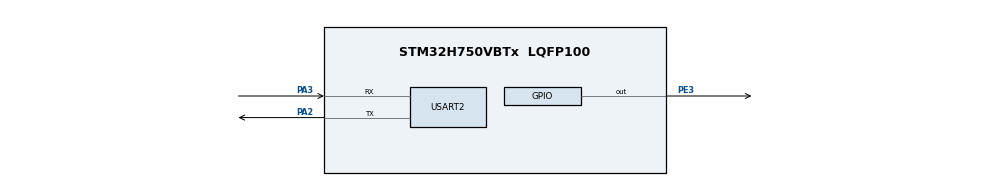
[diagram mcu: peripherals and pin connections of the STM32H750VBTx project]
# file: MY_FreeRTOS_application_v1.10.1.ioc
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CORTEX_M7.AccessPermission-Cortex_Memory_Protection_Unit_Region0_Settings=MPU_REGION_FULL_ACCESS
CORTEX_M7.AccessPermission-Cortex_Memory_Protection_Unit_Region1_Settings=MPU_REGION_FULL_ACCESS
CORTEX_M7.BaseAddress-Cortex_Memory_Protection_Unit_Region0_Settings=0x90000000
CORTEX_M7.BaseAddress-Cortex_Memory_Protection_Unit_Region1_Settings=0x90000000
CORTEX_M7.CPU_DCache=Enabled
CORTEX_M7.CPU_ICache=Enabled
CORTEX_M7.DisableExec-Cortex_Memory_Protection_Unit_Region0_Settings=MPU_INSTRUCTION_ACCESS_DISABLE
CORTEX_M7.DisableExec-Cortex_Memory_Protection_Unit_Region1_Settings=MPU_INSTRUCTION_ACCESS_ENABLE
CORTEX_M7.Enable-Cortex_Memory_Protection_Unit_Region0_Settings=MPU_REGION_ENABLE
CORTEX_M7.Enable-Cortex_Memory_Protection_Unit_Region1_Settings=MPU_REGION_ENABLE
CORTEX_M7.IsBufferable-Cortex_Memory_Protection_Unit_Region0_Settings=MPU_ACCESS_BUFFERABLE
CORTEX_M7.IsBufferable-Cortex_Memory_Protection_Unit_Region1_Settings=MPU_ACCESS_BUFFERABLE
CORTEX_M7.IsCacheable-Cortex_Memory_Protection_Unit_Region0_Settings=MPU_ACCESS_CACHEABLE
CORTEX_M7.IsCacheable-Cortex_Memory_Protection_Unit_Region1_Settings=MPU_ACCESS_CACHEABLE
CORTEX_M7.IsShareable-Cortex_Memory_Protection_Unit_Region1_Settings=MPU_ACCESS_NOT_SHAREABLE
CORTEX_M7.MPU_Control=MPU_PRIVILEGED_DEFAULT
CORTEX_M7.Size-Cortex_Memory_Protection_Unit_Region0_Settings=MPU_REGION_SIZE_8MB
CORTEX_M7.Size-Cortex_Memory_Protection_Unit_Region1_Settings=MPU_REGION_SIZE_1MB
FREERTOS.Tasks01=defaultTask,24,128,StartDefaultTask,Default,NULL,Dynamic,NULL,NULL;my_LED_ON_Task,8,128,Start_LED_ON_Task,Default,NULL,Dynamic,NULL,NULL;my_LED_OFF_Task,8,128,Start_LED_OFF_Task,Default,NULL,Dynamic,NULL,NULL
FREERTOS.configUSE_NEWLIB_REENTRANT=1
Mcu.Family=STM32H7
Mcu.Name=STM32H750VBTx
Mcu.Package=LQFP100
NVIC.PriorityGroup=NVIC_PRIORITYGROUP_4
NVIC.TIM17_IRQn=true\:15\:0\:false\:false\:true\:false\:false\:true\:true
NVIC.TimeBase=TIM17_IRQn
NVIC.TimeBaseIP=TIM17
PA13\ (JTMS/SWDIO).Mode=Serial_Wire
PA13\ (JTMS/SWDIO).Signal=DEBUG_JTMS-SWDIO
PA14\ (JTCK/SWCLK).Mode=Serial_Wire
PA14\ (JTCK/SWCLK).Signal=DEBUG_JTCK-SWCLK
PA2.Mode=Asynchronous
PA2.Signal=USART2_TX
PA3.Mode=Asynchronous
PA3.Signal=USART2_RX
PE3.Signal=GPIO_Output
PH0-OSC_IN\ (PH0).Mode=HSE-External-Oscillator
PH0-OSC_IN\ (PH0).Signal=RCC_OSC_IN
PH1-OSC_OUT\ (PH1).Mode=HSE-External-Oscillator
PH1-OSC_OUT\ (PH1).Signal=RCC_OSC_OUT
ProjectManager.HeapSize=0x200
ProjectManager.StackSize=0x400
ProjectManager.TargetToolchain=STM32CubeIDE
RCC.ADCFreq_Value=50390625
RCC.APB1Freq_Value=100000000
RCC.APB2Freq_Value=100000000
RCC.APB3Freq_Value=100000000
RCC.APB4Freq_Value=100000000
RCC.CortexFreq_Value=200000000
RCC.DIVM1=2
RCC.DIVN1=32
RCC.HCLKFreq_Value=100000000
RCC.HPRE=RCC_HCLK_DIV2
RCC.PLLSourceVirtual=RCC_PLLSOURCE_HSE
RCC.SYSCLKFreq_VALUE=200000000
RCC.SYSCLKSource=RCC_SYSCLKSOURCE_PLLCLK
RCC.USART16CLockSelection=RCC_USART16CLKSOURCE_CSI
RCC.USART234578CLockSelection=RCC_USART234578CLKSOURCE_CSI
RCC.USBFreq_Value=200000000
USART2.VirtualMode-Asynchronous=VM_ASYNC
VP_FREERTOS_VS_CMSIS_V2.Mode=CMSIS_V2
VP_SYS_VS_tim17.Mode=TIM17
board=custom

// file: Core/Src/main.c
/* USER CODE BEGIN Header */
/**
  ******************************************************************************
  * @file           : main.c
  * @brief          : Main program body
  ******************************************************************************
  * @attention
  *
  * Copyright (c) 2022 STMicroelectronics.
  * All rights reserved.
  *
  * This software is licensed under terms that can be found in the LICENSE file
  * in the root directory of this software component.
  * If no LICENSE file comes with this software, it is provided AS-IS.
  *
  ******************************************************************************
  */
/* USER CODE END Header */
#include "main.h"
#include "cmsis_os.h"

/* USER CODE BEGIN Includes */
#include <stdio.h>/* для printf */
#include "stdbool.h"
/* USER CODE END Includes */

/* USER CODE BEGIN PTD */
bool flag;
unsigned long Tim;
/* USER CODE END PTD */

UART_HandleTypeDef huart2;

/* Definitions for defaultTask */
osThreadId_t defaultTaskHandle;
const osThreadAttr_t defaultTask_attributes = {
  .name = "defaultTask",
  .stack_size = 128 * 4,
  .priority = (osPriority_t) osPriorityNormal,
};
/* Definitions for my_LED_ON_Task */
osThreadId_t my_LED_ON_TaskHandle;
const osThreadAttr_t my_LED_ON_Task_attributes = {
  .name = "my_LED_ON_Task",
  .stack_size = 128 * 4,
  .priority = (osPriority_t) osPriorityLow,
};
/* Definitions for my_LED_OFF_Task */
osThreadId_t my_LED_OFF_TaskHandle;
const osThreadAttr_t my_LED_OFF_Task_attributes = {
  .name = "my_LED_OFF_Task",
  .stack_size = 128 * 4,
  .priority = (osPriority_t) osPriorityLow,
};

void SystemClock_Config(void);
static void MPU_Config(void);
static void MX_GPIO_Init(void);
static void MX_USART2_UART_Init(void);
void StartDefaultTask(void *argument);
void Start_LED_ON_Task(void *argument);
void Start_LED_OFF_Task(void *argument);

/* USER CODE BEGIN PFP */
int _write(int file, char *ptr, int len) {
	int i;
	HAL_UART_Transmit(&huart2, (uint8_t*) ptr, len, 50);
	for (i = 0; i < len; i++) {
		ITM_SendChar(*ptr++);
	}
	return len;
}
/* USER CODE END PFP */

int main(void)
{

  /* MPU Configuration--------------------------------------------------------*/
  MPU_Config();

  /* Enable I-Cache---------------------------------------------------------*/
  SCB_EnableICache();

  /* Enable D-Cache---------------------------------------------------------*/
  SCB_EnableDCache();

  /* MCU Configuration--------------------------------------------------------*/

  /* Reset of all peripherals, Initializes the Flash interface and the Systick. */
  HAL_Init();

  /* USER CODE BEGIN Init */
	Tim = HAL_GetTick();
	flag = 1;
  /* USER CODE END Init */

  /* Configure the system clock */
  SystemClock_Config();

  /* Initialize all configured peripherals */
  MX_GPIO_Init();
  MX_USART2_UART_Init();

  /* Init scheduler */
  osKernelInitialize();

  /* Create the thread(s) */
  /* creation of defaultTask */
  defaultTaskHandle = osThreadNew(StartDefaultTask, NULL, &defaultTask_attributes);

  /* creation of my_LED_ON_Task */
  my_LED_ON_TaskHandle = osThreadNew(Start_LED_ON_Task, NULL, &my_LED_ON_Task_attributes);

  /* creation of my_LED_OFF_Task */
  my_LED_OFF_TaskHandle = osThreadNew(Start_LED_OFF_Task, NULL, &my_LED_OFF_Task_attributes);

  /* Start scheduler */
  osKernelStart();

  /* We should never get here as control is now taken by the scheduler */
  /* Infinite loop */
  while (1)
  {

  }
}

void SystemClock_Config(void)
{
  RCC_OscInitTypeDef RCC_OscInitStruct = {0};
  RCC_ClkInitTypeDef RCC_ClkInitStruct = {0};

  /** Supply configuration update enable
  */
  HAL_PWREx_ConfigSupply(PWR_LDO_SUPPLY);

  /** Configure the main internal regulator output voltage
  */
  __HAL_PWR_VOLTAGESCALING_CONFIG(PWR_REGULATOR_VOLTAGE_SCALE3);

  while(!__HAL_PWR_GET_FLAG(PWR_FLAG_VOSRDY)) {}

  /** Initializes the RCC Oscillators according to the specified parameters
  * in the RCC_OscInitTypeDef structure.
  */
  RCC_OscInitStruct.OscillatorType = RCC_OSCILLATORTYPE_CSI|RCC_OSCILLATORTYPE_HSE;
  RCC_OscInitStruct.HSEState = RCC_HSE_ON;
  RCC_OscInitStruct.CSIState = RCC_CSI_ON;
  RCC_OscInitStruct.CSICalibrationValue = RCC_CSICALIBRATION_DEFAULT;
  RCC_OscInitStruct.PLL.PLLState = RCC_PLL_ON;
  RCC_OscInitStruct.PLL.PLLSource = RCC_PLLSOURCE_HSE;
  RCC_OscInitStruct.PLL.PLLM = 2;
  RCC_OscInitStruct.PLL.PLLN = 32;
  RCC_OscInitStruct.PLL.PLLP = 2;
  RCC_OscInitStruct.PLL.PLLQ = 2;
  RCC_OscInitStruct.PLL.PLLR = 2;
  RCC_OscInitStruct.PLL.PLLRGE = RCC_PLL1VCIRANGE_3;
  RCC_OscInitStruct.PLL.PLLVCOSEL = RCC_PLL1VCOWIDE;
  RCC_OscInitStruct.PLL.PLLFRACN = 0;
  if (HAL_RCC_OscConfig(&RCC_OscInitStruct) != HAL_OK)
  {
    Error_Handler();
  }

  /** Initializes the CPU, AHB and APB buses clocks
  */
  RCC_ClkInitStruct.ClockType = RCC_CLOCKTYPE_HCLK|RCC_CLOCKTYPE_SYSCLK
                              |RCC_CLOCKTYPE_PCLK1|RCC_CLOCKTYPE_PCLK2
                              |RCC_CLOCKTYPE_D3PCLK1|RCC_CLOCKTYPE_D1PCLK1;
  RCC_ClkInitStruct.SYSCLKSource = RCC_SYSCLKSOURCE_PLLCLK;
  RCC_ClkInitStruct.SYSCLKDivider = RCC_SYSCLK_DIV1;
  RCC_ClkInitStruct.AHBCLKDivider = RCC_HCLK_DIV2;
  RCC_ClkInitStruct.APB3CLKDivider = RCC_APB3_DIV1;
  RCC_ClkInitStruct.APB1CLKDivider = RCC_APB1_DIV1;
  RCC_ClkInitStruct.APB2CLKDivider = RCC_APB2_DIV1;
  RCC_ClkInitStruct.APB4CLKDivider = RCC_APB4_DIV1;

  if (HAL_RCC_ClockConfig(&RCC_ClkInitStruct, FLASH_LATENCY_2) != HAL_OK)
  {
    Error_Handler();
  }
}

static void MX_USART2_UART_Init(void)
{

  huart2.Instance = USART2;
  huart2.Init.BaudRate = 115200;
  huart2.Init.WordLength = UART_WORDLENGTH_8B;
  huart2.Init.StopBits = UART_STOPBITS_1;
  huart2.Init.Parity = UART_PARITY_NONE;
  huart2.Init.Mode = UART_MODE_TX_RX;
  huart2.Init.HwFlowCtl = UART_HWCONTROL_NONE;
  huart2.Init.OverSampling = UART_OVERSAMPLING_16;
  huart2.Init.OneBitSampling = UART_ONE_BIT_SAMPLE_DISABLE;
  huart2.Init.ClockPrescaler = UART_PRESCALER_DIV1;
  huart2.AdvancedInit.AdvFeatureInit = UART_ADVFEATURE_NO_INIT;
  if (HAL_UART_Init(&huart2) != HAL_OK)
  {
    Error_Handler();
  }
  if (HAL_UARTEx_SetTxFifoThreshold(&huart2, UART_TXFIFO_THRESHOLD_1_8) != HAL_OK)
  {
    Error_Handler();
  }
  if (HAL_UARTEx_SetRxFifoThreshold(&huart2, UART_RXFIFO_THRESHOLD_1_8) != HAL_OK)
  {
    Error_Handler();
  }
  if (HAL_UARTEx_DisableFifoMode(&huart2) != HAL_OK)
  {
    Error_Handler();
  }

}

static void MX_GPIO_Init(void)
{
  GPIO_InitTypeDef GPIO_InitStruct = {0};

  /* GPIO Ports Clock Enable */
  __HAL_RCC_GPIOE_CLK_ENABLE();
  __HAL_RCC_GPIOH_CLK_ENABLE();
  __HAL_RCC_GPIOA_CLK_ENABLE();

  /*Configure GPIO pin Output Level */
  HAL_GPIO_WritePin(GPIOE, GPIO_PIN_3, GPIO_PIN_RESET);

  /*Configure GPIO pin : PE3 */
  GPIO_InitStruct.Pin = GPIO_PIN_3;
  GPIO_InitStruct.Mode = GPIO_MODE_OUTPUT_PP;
  GPIO_InitStruct.Pull = GPIO_NOPULL;
  GPIO_InitStruct.Speed = GPIO_SPEED_FREQ_LOW;
  HAL_GPIO_Init(GPIOE, &GPIO_InitStruct);

}

void StartDefaultTask(void *argument)
{
  for(;;)
  {
    osDelay(1);
  }
}

void Start_LED_ON_Task(void *argument)
{
  /* USER CODE BEGIN Start_LED_ON_Task */
  /* Infinite loop */
  for(;;)
  {
		if (flag == 1) {
			if (HAL_GetTick() - Tim >= 250) {
				printf("Hello from QSPI, LED if ON! \r\n");
				flag = 0;
				Tim = HAL_GetTick();
			}
		}
		HAL_GPIO_WritePin(GPIOE, GPIO_PIN_3, flag);
		//osDelay(1);
	}
  /* USER CODE END Start_LED_ON_Task */
}

void Start_LED_OFF_Task(void *argument)
{
  /* USER CODE BEGIN Start_LED_OFF_Task */
  /* Infinite loop */
  for(;;)
  {
		if (flag == 0) {
			if (HAL_GetTick() - Tim >= 250) {
				printf("Hello from QSPI, LED if OFF! \r\n");
				flag = 1;
				Tim = HAL_GetTick();
			}
		}
		HAL_GPIO_WritePin(GPIOE, GPIO_PIN_3, flag);
		//osDelay(1);
	}
  /* USER CODE END Start_LED_OFF_Task */
}

/* MPU Configuration */

void MPU_Config(void)
{
  MPU_Region_InitTypeDef MPU_InitStruct = {0};

  /* Disables the MPU */
  HAL_MPU_Disable();

  /** Initializes and configures the Region and the memory to be protected
  */
  MPU_InitStruct.Enable = MPU_REGION_ENABLE;
  MPU_InitStruct.Number = MPU_REGION_NUMBER0;
  MPU_InitStruct.BaseAddress = 0x90000000;
  MPU_InitStruct.Size = MPU_REGION_SIZE_8MB;
  MPU_InitStruct.SubRegionDisable = 0x0;
  MPU_InitStruct.TypeExtField = MPU_TEX_LEVEL0;
  MPU_InitStruct.AccessPermission = MPU_REGION_FULL_ACCESS;
  MPU_InitStruct.DisableExec = MPU_INSTRUCTION_ACCESS_DISABLE;
  MPU_InitStruct.IsShareable = MPU_ACCESS_NOT_SHAREABLE;
  MPU_InitStruct.IsCacheable = MPU_ACCESS_CACHEABLE;
  MPU_InitStruct.IsBufferable = MPU_ACCESS_BUFFERABLE;

  HAL_MPU_ConfigRegion(&MPU_InitStruct);

  /** Initializes and configures the Region and the memory to be protected
  */
  MPU_InitStruct.Number = MPU_REGION_NUMBER1;
  MPU_InitStruct.Size = MPU_REGION_SIZE_1MB;
  MPU_InitStruct.DisableExec = MPU_INSTRUCTION_ACCESS_ENABLE;

  HAL_MPU_ConfigRegion(&MPU_InitStruct);
  /* Enables the MPU */
  HAL_MPU_Enable(MPU_PRIVILEGED_DEFAULT);

}

void HAL_TIM_PeriodElapsedCallback(TIM_HandleTypeDef *htim)
{
  if (htim->Instance == TIM17) {
    HAL_IncTick();
  }
}

void Error_Handler(void)
{
  __disable_irq();
  while (1)
  {
  }
}
